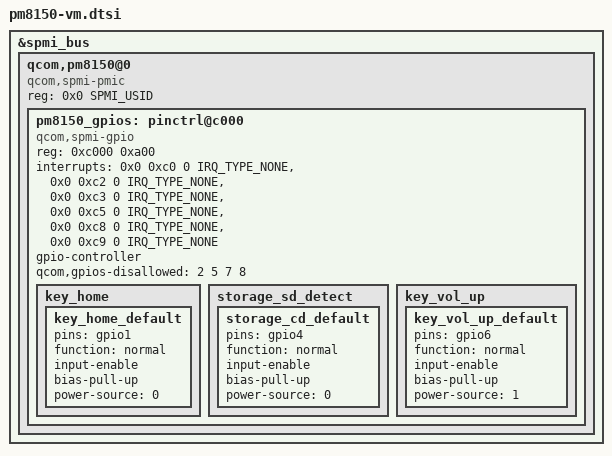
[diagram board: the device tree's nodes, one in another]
/*
 * Copyright (c) 2019, The Linux Foundation. All rights reserved.
 *
 * This program is free software; you can redistribute it and/or modify
 * it under the terms of the GNU General Public License version 2 and
 * only version 2 as published by the Free Software Foundation.
 *
 * This program is distributed in the hope that it will be useful,
 * but WITHOUT ANY WARRANTY; without even the implied warranty of
 * MERCHANTABILITY or FITNESS FOR A PARTICULAR PURPOSE.  See the
 * GNU General Public License for more details.
 */

#include <dt-bindings/clock/qcom,rpmh.h>
#include <dt-bindings/input/input.h>
#include <dt-bindings/input/qcom,qpnp-power-on.h>
#include <dt-bindings/interrupt-controller/irq.h>
#include <dt-bindings/spmi/spmi.h>
#include <dt-bindings/iio/qcom,spmi-vadc.h>

&spmi_bus {
	qcom,pm8150@0 {
		compatible = "qcom,spmi-pmic";
		reg = <0x0 SPMI_USID>;
		#address-cells = <2>;
		#size-cells = <0>;

		pm8150_gpios: pinctrl@c000 {
			compatible = "qcom,spmi-gpio";
			reg = <0xc000 0xa00>;
			interrupts = <0x0 0xc0 0 IRQ_TYPE_NONE>,
					<0x0 0xc2 0 IRQ_TYPE_NONE>,
					<0x0 0xc3 0 IRQ_TYPE_NONE>,
					<0x0 0xc5 0 IRQ_TYPE_NONE>,
					<0x0 0xc8 0 IRQ_TYPE_NONE>,
					<0x0 0xc9 0 IRQ_TYPE_NONE>;
			interrupt-names = "pm8150_gpio1", "pm8150_gpio3",
					"pm8150_gpio4", "pm8150_gpio6",
					"pm8150_gpio9", "pm8150_gpio10";
			gpio-controller;
			#gpio-cells = <2>;
			qcom,gpios-disallowed = <2 5 7 8>;
		};
	};
};

&pm8150_gpios {
	key_home {
		key_home_default: key_home_default {
			pins = "gpio1";
			function = "normal";
			input-enable;
			bias-pull-up;
			power-source = <0>;
		};
	};

	storage_sd_detect {
		storage_cd_default: storage_cd_default {
			pins = "gpio4";
			function = "normal";
			input-enable;
			bias-pull-up;
			power-source = <0>;
		};
	};

	key_vol_up {
		key_vol_up_default: key_vol_up_default {
			pins = "gpio6";
			function = "normal";
			input-enable;
			bias-pull-up;
			power-source = <1>;
		};
	};
};
